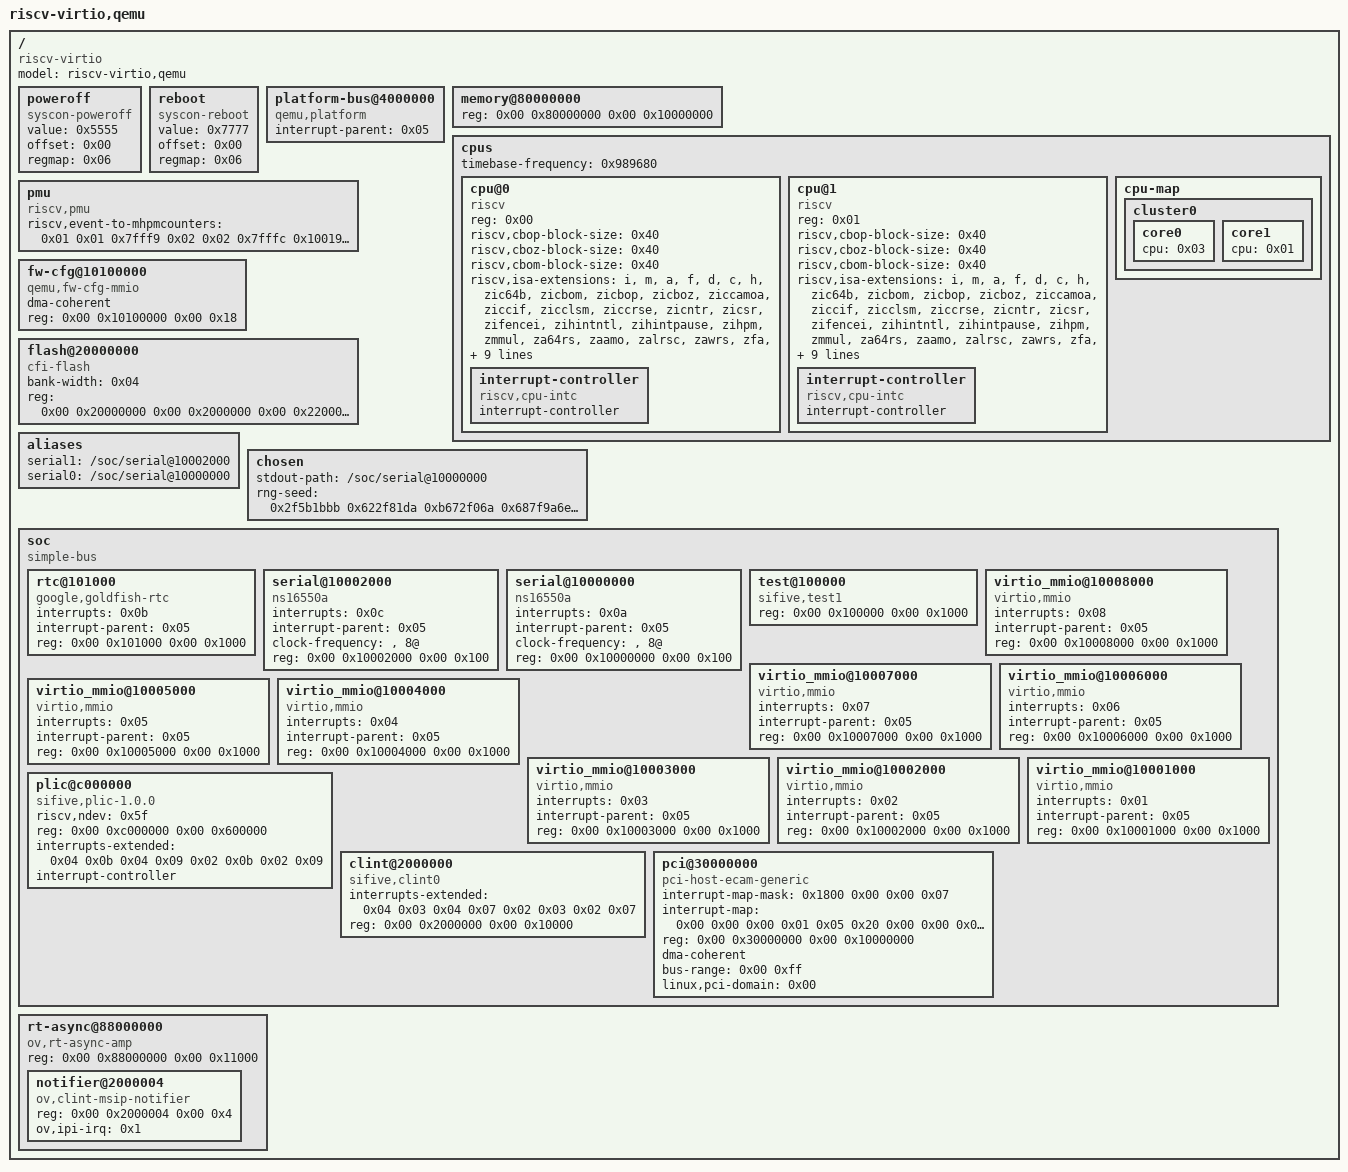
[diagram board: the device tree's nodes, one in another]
/dts-v1/;

/memreserve/	0x0000000088000000 0x0000000000011000;
/ {
	#address-cells = <0x02>;
	#size-cells = <0x02>;
	compatible = "riscv-virtio";
	model = "riscv-virtio,qemu";

	poweroff {
		value = <0x5555>;
		offset = <0x00>;
		regmap = <0x06>;
		compatible = "syscon-poweroff";
	};

	reboot {
		value = <0x7777>;
		offset = <0x00>;
		regmap = <0x06>;
		compatible = "syscon-reboot";
	};

	platform-bus@4000000 {
		interrupt-parent = <0x05>;
		ranges = <0x00 0x00 0x4000000 0x2000000>;
		#address-cells = <0x01>;
		#size-cells = <0x01>;
		compatible = "qemu,platform", "simple-bus";
	};

	memory@80000000 {
		device_type = "memory";
		reg = <0x00 0x80000000 0x00 0x10000000>;
	};

	cpus {
		#address-cells = <0x01>;
		#size-cells = <0x00>;
		timebase-frequency = <0x989680>;

		cpu@0 {
			phandle = <0x03>;
			device_type = "cpu";
			reg = <0x00>;
			status = "okay";
			compatible = "riscv";
			riscv,cbop-block-size = <0x40>;
			riscv,cboz-block-size = <0x40>;
			riscv,cbom-block-size = <0x40>;
			riscv,isa-extensions = "i", "m", "a", "f", "d", "c", "h", "zic64b", "zicbom", "zicbop", "zicboz", "ziccamoa", "ziccif", "zicclsm", "ziccrse", "zicntr", "zicsr", "zifencei", "zihintntl", "zihintpause", "zihpm", "zmmul", "za64rs", "zaamo", "zalrsc", "zawrs", "zfa", "zca", "zcd", "zba", "zbb", "zbc", "zbs", "sdtrig", "shcounterenw", "shgatpa", "shtvala", "shvsatpa", "shvstvala", "shvstvecd", "ssccptr", "sscounterenw", "ssstrict", "sstc", "sstvala", "sstvecd", "ssu64xl", "svadu", "svvptc";
			riscv,isa-base = "rv64i";
			riscv,isa = "rv64imafdch_zic64b_zicbom_zicbop_zicboz_ziccamoa_ziccif_zicclsm_ziccrse_zicntr_zicsr_zifencei_zihintntl_zihintpause_zihpm_zmmul_za64rs_zaamo_zalrsc_zawrs_zfa_zca_zcd_zba_zbb_zbc_zbs_sdtrig_shcounterenw_shgatpa_shtvala_shvsatpa_shvstvala_shvstvecd_ssccptr_sscounterenw_ssstrict_sstc_sstvala_sstvecd_ssu64xl_svadu_svvptc";
			mmu-type = "riscv,sv57";

			interrupt-controller {
				#interrupt-cells = <0x01>;
				interrupt-controller;
				compatible = "riscv,cpu-intc";
				phandle = <0x04>;
			};
		};

		cpu@1 {
			phandle = <0x01>;
			device_type = "cpu";
			reg = <0x01>;
			status = "okay";
			compatible = "riscv";
			riscv,cbop-block-size = <0x40>;
			riscv,cboz-block-size = <0x40>;
			riscv,cbom-block-size = <0x40>;
			riscv,isa-extensions = "i", "m", "a", "f", "d", "c", "h", "zic64b", "zicbom", "zicbop", "zicboz", "ziccamoa", "ziccif", "zicclsm", "ziccrse", "zicntr", "zicsr", "zifencei", "zihintntl", "zihintpause", "zihpm", "zmmul", "za64rs", "zaamo", "zalrsc", "zawrs", "zfa", "zca", "zcd", "zba", "zbb", "zbc", "zbs", "sdtrig", "shcounterenw", "shgatpa", "shtvala", "shvsatpa", "shvstvala", "shvstvecd", "ssccptr", "sscounterenw", "ssstrict", "sstc", "sstvala", "sstvecd", "ssu64xl", "svadu", "svvptc";
			riscv,isa-base = "rv64i";
			riscv,isa = "rv64imafdch_zic64b_zicbom_zicbop_zicboz_ziccamoa_ziccif_zicclsm_ziccrse_zicntr_zicsr_zifencei_zihintntl_zihintpause_zihpm_zmmul_za64rs_zaamo_zalrsc_zawrs_zfa_zca_zcd_zba_zbb_zbc_zbs_sdtrig_shcounterenw_shgatpa_shtvala_shvsatpa_shvstvala_shvstvecd_ssccptr_sscounterenw_ssstrict_sstc_sstvala_sstvecd_ssu64xl_svadu_svvptc";
			mmu-type = "riscv,sv57";

			interrupt-controller {
				#interrupt-cells = <0x01>;
				interrupt-controller;
				compatible = "riscv,cpu-intc";
				phandle = <0x02>;
			};
		};

		cpu-map {

			cluster0 {

				core0 {
					cpu = <0x03>;
				};

				core1 {
					cpu = <0x01>;
				};
			};
		};
	};

	pmu {
		riscv,event-to-mhpmcounters = <0x01 0x01 0x7fff9 0x02 0x02 0x7fffc 0x10019 0x10019 0x7fff8 0x1001b 0x1001b 0x7fff8 0x10021 0x10021 0x7fff8>;
		compatible = "riscv,pmu";
	};

	fw-cfg@10100000 {
		dma-coherent;
		reg = <0x00 0x10100000 0x00 0x18>;
		compatible = "qemu,fw-cfg-mmio";
	};

	flash@20000000 {
		bank-width = <0x04>;
		reg = <0x00 0x20000000 0x00 0x2000000 0x00 0x22000000 0x00 0x2000000>;
		compatible = "cfi-flash";
	};

	aliases {
		serial1 = "/soc/serial@10002000";
		serial0 = "/soc/serial@10000000";
	};

	chosen {
		stdout-path = "/soc/serial@10000000";
		rng-seed = <0x2f5b1bbb 0x622f81da 0xb672f06a 0x687f9a6e 0x66028f86 0xb8f40d3a 0x802aecbb 0x71446834>;
	};

	soc {
		#address-cells = <0x02>;
		#size-cells = <0x02>;
		compatible = "simple-bus";
		ranges;

		rtc@101000 {
			interrupts = <0x0b>;
			interrupt-parent = <0x05>;
			reg = <0x00 0x101000 0x00 0x1000>;
			compatible = "google,goldfish-rtc";
		};

		serial@10002000 {
			interrupts = <0x0c>;
			interrupt-parent = <0x05>;
			clock-frequency = "", "8@";
			reg = <0x00 0x10002000 0x00 0x100>;
			compatible = "ns16550a";
		};

		serial@10000000 {
			interrupts = <0x0a>;
			interrupt-parent = <0x05>;
			clock-frequency = "", "8@";
			reg = <0x00 0x10000000 0x00 0x100>;
			compatible = "ns16550a";
		};

		test@100000 {
			phandle = <0x06>;
			reg = <0x00 0x100000 0x00 0x1000>;
			compatible = "sifive,test1", "sifive,test0", "syscon";
		};

		virtio_mmio@10008000 {
			interrupts = <0x08>;
			interrupt-parent = <0x05>;
			reg = <0x00 0x10008000 0x00 0x1000>;
			compatible = "virtio,mmio";
		};

		virtio_mmio@10007000 {
			interrupts = <0x07>;
			interrupt-parent = <0x05>;
			reg = <0x00 0x10007000 0x00 0x1000>;
			compatible = "virtio,mmio";
		};

		virtio_mmio@10006000 {
			interrupts = <0x06>;
			interrupt-parent = <0x05>;
			reg = <0x00 0x10006000 0x00 0x1000>;
			compatible = "virtio,mmio";
		};

		virtio_mmio@10005000 {
			interrupts = <0x05>;
			interrupt-parent = <0x05>;
			reg = <0x00 0x10005000 0x00 0x1000>;
			compatible = "virtio,mmio";
		};

		virtio_mmio@10004000 {
			interrupts = <0x04>;
			interrupt-parent = <0x05>;
			reg = <0x00 0x10004000 0x00 0x1000>;
			compatible = "virtio,mmio";
		};

		virtio_mmio@10003000 {
			interrupts = <0x03>;
			interrupt-parent = <0x05>;
			reg = <0x00 0x10003000 0x00 0x1000>;
			compatible = "virtio,mmio";
		};

		virtio_mmio@10002000 {
			interrupts = <0x02>;
			interrupt-parent = <0x05>;
			reg = <0x00 0x10002000 0x00 0x1000>;
			compatible = "virtio,mmio";
		};

		virtio_mmio@10001000 {
			interrupts = <0x01>;
			interrupt-parent = <0x05>;
			reg = <0x00 0x10001000 0x00 0x1000>;
			compatible = "virtio,mmio";
		};

		plic@c000000 {
			phandle = <0x05>;
			riscv,ndev = <0x5f>;
			reg = <0x00 0xc000000 0x00 0x600000>;
			interrupts-extended = <0x04 0x0b 0x04 0x09 0x02 0x0b 0x02 0x09>;
			interrupt-controller;
			compatible = "sifive,plic-1.0.0", "riscv,plic0";
			#address-cells = <0x00>;
			#interrupt-cells = <0x01>;
		};

		clint@2000000 {
			interrupts-extended = <0x04 0x03 0x04 0x07 0x02 0x03 0x02 0x07>;
			reg = <0x00 0x2000000 0x00 0x10000>;
			compatible = "sifive,clint0", "riscv,clint0";
		};

		pci@30000000 {
			interrupt-map-mask = <0x1800 0x00 0x00 0x07>;
			interrupt-map = <0x00 0x00 0x00 0x01 0x05 0x20 0x00 0x00 0x00 0x02 0x05 0x21 0x00 0x00 0x00 0x03 0x05 0x22 0x00 0x00 0x00 0x04 0x05 0x23 0x800 0x00 0x00 0x01 0x05 0x21 0x800 0x00 0x00 0x02 0x05 0x22 0x800 0x00 0x00 0x03 0x05 0x23 0x800 0x00 0x00 0x04 0x05 0x20 0x1000 0x00 0x00 0x01 0x05 0x22 0x1000 0x00 0x00 0x02 0x05 0x23 0x1000 0x00 0x00 0x03 0x05 0x20 0x1000 0x00 0x00 0x04 0x05 0x21 0x1800 0x00 0x00 0x01 0x05 0x23 0x1800 0x00 0x00 0x02 0x05 0x20 0x1800 0x00 0x00 0x03 0x05 0x21 0x1800 0x00 0x00 0x04 0x05 0x22>;
			ranges = <0x1000000 0x00 0x00 0x00 0x3000000 0x00 0x10000 0x2000000 0x00 0x40000000 0x00 0x40000000 0x00 0x40000000 0x3000000 0x04 0x00 0x04 0x00 0x04 0x00>;
			reg = <0x00 0x30000000 0x00 0x10000000>;
			dma-coherent;
			bus-range = <0x00 0xff>;
			linux,pci-domain = <0x00>;
			device_type = "pci";
			compatible = "pci-host-ecam-generic";
			#size-cells = <0x02>;
			#interrupt-cells = <0x01>;
			#address-cells = <0x03>;
		};
	};

	rt-async@88000000 {
		compatible = "ov,rt-async-amp";
		reg = <0x00 0x88000000 0x00 0x11000>;
		// 显式声明子节点的 cell 尺寸，避免 fdt-parser 解析 notifier.reg
		// 时回退到默认值（默认 #size-cells=1）导致 reg 错位/panic。
		#address-cells = <0x02>;
		#size-cells = <0x02>;

		notifier@2000004 {
			compatible = "ov,clint-msip-notifier";
			// MSIP1 物理地址 = CLINTBASE(0x2000000) + 0x4
			reg = <0x00 0x2000004 0x00 0x4>;
			// SSI cause 号 (riscv64 软中断 = 1)
			ov,ipi-irq = <0x1>;
		};
	};
};
